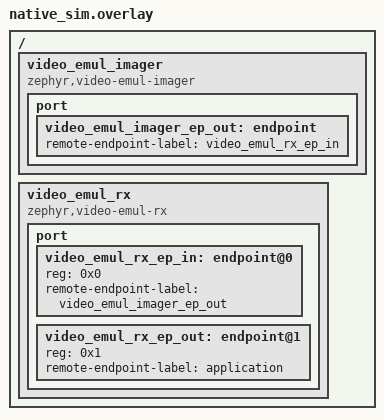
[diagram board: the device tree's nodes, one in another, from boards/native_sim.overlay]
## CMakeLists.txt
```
# SPDX-License-Identifier: Apache-2.0

cmake_minimum_required(VERSION 3.20.0)
find_package(Zephyr REQUIRED HINTS $ENV{ZEPHYR_BASE})
project(video_shell)

FILE(GLOB app_sources src/*.c)
target_sources(app PRIVATE ${app_sources})
```

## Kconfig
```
# SPDX-License-Identifier: Apache-2.0

source "Kconfig.zephyr"
```

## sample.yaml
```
sample:
  name: Video shell
tests:
  sample.video.shell:
    tags: video
    extra_args:
      - platform:mimxrt1170_evk/mimxrt1176/cm7:SHIELD="nxp_btb44_ov5640"
    harness: console
    harness_config:
      type: multi_line
      regex:
        - "You can now start using the video shell"
    platform_allow:
      - mimxrt1170_evk/mimxrt1176/cm7
      - native_sim
    integration_platforms:
      - mimxrt1170_evk/mimxrt1176/cm7
      - native_sim
```

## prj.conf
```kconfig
CONFIG_VIDEO=y
CONFIG_VIDEO_SW_GENERATOR=y
CONFIG_SHELL=y
CONFIG_DEVICE_SHELL=y
CONFIG_VIDEO_SHELL=y
CONFIG_LOG=y
```

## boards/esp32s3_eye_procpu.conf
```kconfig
CONFIG_VIDEO_BUFFER_POOL_SZ_MAX=40000
CONFIG_VIDEO_BUFFER_POOL_NUM_MAX=3
CONFIG_ESP_SPIRAM=y
CONFIG_SPIRAM_MODE_OCT=y
CONFIG_VIDEO_BUFFER_POOL_ALIGN=32
CONFIG_DMA_ESP32_MAX_DESCRIPTOR_NUM=64
CONFIG_VIDEO_BUFFER_USE_SHARED_MULTI_HEAP=y
CONFIG_VIDEO_BUFFER_SMH_ATTRIBUTE=2
```

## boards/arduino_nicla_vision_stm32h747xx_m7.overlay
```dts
/*
 * Copyright 2024 Felipe Neves
 *
 * SPDX-License-Identifier: Apache-2.0
 */

/ {
	chosen {
		zephyr,console = &cdc_acm_uart0;
		zephyr,shell-uart = &cdc_acm_uart0;
	};
};

zephyr_udc0: &usbotg_hs {
	status = "okay";
	cdc_acm_uart0: cdc_acm_uart0 {
		compatible = "zephyr,cdc-acm-uart";
	};
};
```

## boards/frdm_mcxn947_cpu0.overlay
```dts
/*
 * Copyright 2024 NXP
 *
 * SPDX-License-Identifier: Apache-2.0
 */

/ {
	chosen {
		zephyr,camera = &video_sdma;
	};
};
```

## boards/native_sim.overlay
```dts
/*
 * Copyright (c) 2024 tinyVision.ai Inc.
 *
 * SPDX-License-Identifier: Apache-2.0
 */

/ {
	video_emul_imager: video_emul_imager {
		compatible = "zephyr,video-emul-imager";

		port {
			video_emul_imager_ep_out: endpoint {
				remote-endpoint-label = "video_emul_rx_ep_in";
			};
		};
	};

	video_emul_rx: video_emul_rx {
		compatible = "zephyr,video-emul-rx";

		port {
			#address-cells = <1>;
			#size-cells = <0>;

			video_emul_rx_ep_in: endpoint@0 {
				reg = <0x0>;
				remote-endpoint-label = "video_emul_imager_ep_out";
			};

			video_emul_rx_ep_out: endpoint@1 {
				reg = <0x1>;
				remote-endpoint-label = "application";
			};
		};
	};
};
```

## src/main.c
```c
/*
 * Copyright The Zephyr Project Contributors
 *
 * SPDX-License-Identifier: Apache-2.0
 */

#include <zephyr/logging/log.h>

LOG_MODULE_REGISTER(main, LOG_LEVEL_INF);

int main(void)
{
	LOG_INF("You can now start using the video shell");
	return 0;
}
```
